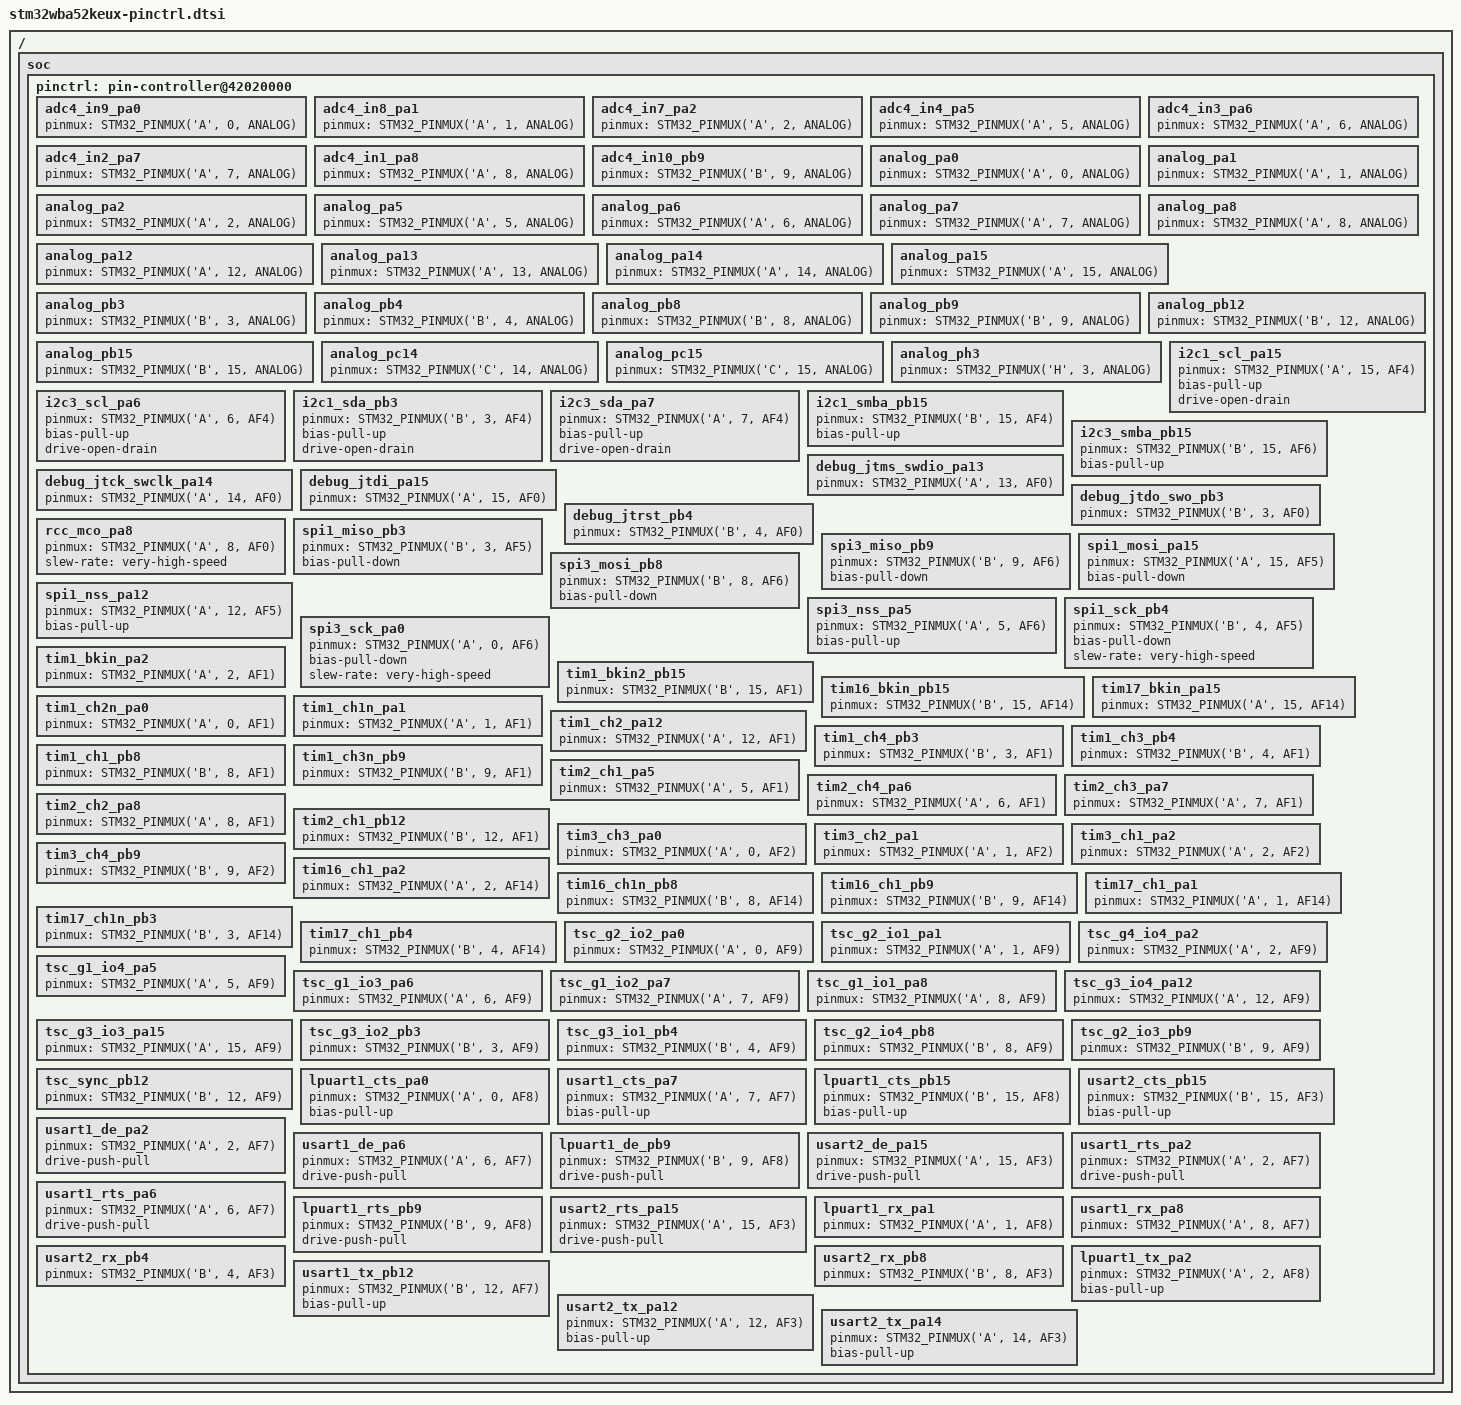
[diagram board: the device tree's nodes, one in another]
/*
 * NOTE: Autogenerated file using genpinctrl.py
 *
 * SPDX-License-Identifier: Apache-2.0
 */

#include <zephyr/dt-bindings/pinctrl/stm32-pinctrl.h>

/ {
	soc {
		pinctrl: pin-controller@42020000 {

			/* ADC_IN / ADC_INN / ADC_INP */

			/omit-if-no-ref/ adc4_in9_pa0: adc4_in9_pa0 {
				pinmux = <STM32_PINMUX('A', 0, ANALOG)>;
			};

			/omit-if-no-ref/ adc4_in8_pa1: adc4_in8_pa1 {
				pinmux = <STM32_PINMUX('A', 1, ANALOG)>;
			};

			/omit-if-no-ref/ adc4_in7_pa2: adc4_in7_pa2 {
				pinmux = <STM32_PINMUX('A', 2, ANALOG)>;
			};

			/omit-if-no-ref/ adc4_in4_pa5: adc4_in4_pa5 {
				pinmux = <STM32_PINMUX('A', 5, ANALOG)>;
			};

			/omit-if-no-ref/ adc4_in3_pa6: adc4_in3_pa6 {
				pinmux = <STM32_PINMUX('A', 6, ANALOG)>;
			};

			/omit-if-no-ref/ adc4_in2_pa7: adc4_in2_pa7 {
				pinmux = <STM32_PINMUX('A', 7, ANALOG)>;
			};

			/omit-if-no-ref/ adc4_in1_pa8: adc4_in1_pa8 {
				pinmux = <STM32_PINMUX('A', 8, ANALOG)>;
			};

			/omit-if-no-ref/ adc4_in10_pb9: adc4_in10_pb9 {
				pinmux = <STM32_PINMUX('B', 9, ANALOG)>;
			};

			/* Analog */

			/omit-if-no-ref/ analog_pa0: analog_pa0 {
				pinmux = <STM32_PINMUX('A', 0, ANALOG)>;
			};

			/omit-if-no-ref/ analog_pa1: analog_pa1 {
				pinmux = <STM32_PINMUX('A', 1, ANALOG)>;
			};

			/omit-if-no-ref/ analog_pa2: analog_pa2 {
				pinmux = <STM32_PINMUX('A', 2, ANALOG)>;
			};

			/omit-if-no-ref/ analog_pa5: analog_pa5 {
				pinmux = <STM32_PINMUX('A', 5, ANALOG)>;
			};

			/omit-if-no-ref/ analog_pa6: analog_pa6 {
				pinmux = <STM32_PINMUX('A', 6, ANALOG)>;
			};

			/omit-if-no-ref/ analog_pa7: analog_pa7 {
				pinmux = <STM32_PINMUX('A', 7, ANALOG)>;
			};

			/omit-if-no-ref/ analog_pa8: analog_pa8 {
				pinmux = <STM32_PINMUX('A', 8, ANALOG)>;
			};

			/omit-if-no-ref/ analog_pa12: analog_pa12 {
				pinmux = <STM32_PINMUX('A', 12, ANALOG)>;
			};

			/omit-if-no-ref/ analog_pa13: analog_pa13 {
				pinmux = <STM32_PINMUX('A', 13, ANALOG)>;
			};

			/omit-if-no-ref/ analog_pa14: analog_pa14 {
				pinmux = <STM32_PINMUX('A', 14, ANALOG)>;
			};

			/omit-if-no-ref/ analog_pa15: analog_pa15 {
				pinmux = <STM32_PINMUX('A', 15, ANALOG)>;
			};

			/omit-if-no-ref/ analog_pb3: analog_pb3 {
				pinmux = <STM32_PINMUX('B', 3, ANALOG)>;
			};

			/omit-if-no-ref/ analog_pb4: analog_pb4 {
				pinmux = <STM32_PINMUX('B', 4, ANALOG)>;
			};

			/omit-if-no-ref/ analog_pb8: analog_pb8 {
				pinmux = <STM32_PINMUX('B', 8, ANALOG)>;
			};

			/omit-if-no-ref/ analog_pb9: analog_pb9 {
				pinmux = <STM32_PINMUX('B', 9, ANALOG)>;
			};

			/omit-if-no-ref/ analog_pb12: analog_pb12 {
				pinmux = <STM32_PINMUX('B', 12, ANALOG)>;
			};

			/omit-if-no-ref/ analog_pb15: analog_pb15 {
				pinmux = <STM32_PINMUX('B', 15, ANALOG)>;
			};

			/omit-if-no-ref/ analog_pc14: analog_pc14 {
				pinmux = <STM32_PINMUX('C', 14, ANALOG)>;
			};

			/omit-if-no-ref/ analog_pc15: analog_pc15 {
				pinmux = <STM32_PINMUX('C', 15, ANALOG)>;
			};

			/omit-if-no-ref/ analog_ph3: analog_ph3 {
				pinmux = <STM32_PINMUX('H', 3, ANALOG)>;
			};

			/* I2C_SCL */

			/omit-if-no-ref/ i2c1_scl_pa15: i2c1_scl_pa15 {
				pinmux = <STM32_PINMUX('A', 15, AF4)>;
				bias-pull-up;
				drive-open-drain;
			};

			/omit-if-no-ref/ i2c3_scl_pa6: i2c3_scl_pa6 {
				pinmux = <STM32_PINMUX('A', 6, AF4)>;
				bias-pull-up;
				drive-open-drain;
			};

			/* I2C_SDA */

			/omit-if-no-ref/ i2c1_sda_pb3: i2c1_sda_pb3 {
				pinmux = <STM32_PINMUX('B', 3, AF4)>;
				bias-pull-up;
				drive-open-drain;
			};

			/omit-if-no-ref/ i2c3_sda_pa7: i2c3_sda_pa7 {
				pinmux = <STM32_PINMUX('A', 7, AF4)>;
				bias-pull-up;
				drive-open-drain;
			};

			/* I2C_SMBA */

			/omit-if-no-ref/ i2c1_smba_pb15: i2c1_smba_pb15 {
				pinmux = <STM32_PINMUX('B', 15, AF4)>;
				bias-pull-up;
			};

			/omit-if-no-ref/ i2c3_smba_pb15: i2c3_smba_pb15 {
				pinmux = <STM32_PINMUX('B', 15, AF6)>;
				bias-pull-up;
			};

			/* JTAG PORT */

			/omit-if-no-ref/ debug_jtms_swdio_pa13: debug_jtms_swdio_pa13 {
				pinmux = <STM32_PINMUX('A', 13, AF0)>;
			};

			/omit-if-no-ref/ debug_jtck_swclk_pa14: debug_jtck_swclk_pa14 {
				pinmux = <STM32_PINMUX('A', 14, AF0)>;
			};

			/omit-if-no-ref/ debug_jtdi_pa15: debug_jtdi_pa15 {
				pinmux = <STM32_PINMUX('A', 15, AF0)>;
			};

			/omit-if-no-ref/ debug_jtdo_swo_pb3: debug_jtdo_swo_pb3 {
				pinmux = <STM32_PINMUX('B', 3, AF0)>;
			};

			/omit-if-no-ref/ debug_jtrst_pb4: debug_jtrst_pb4 {
				pinmux = <STM32_PINMUX('B', 4, AF0)>;
			};

			/* RCC_MCO */

			/omit-if-no-ref/ rcc_mco_pa8: rcc_mco_pa8 {
				pinmux = <STM32_PINMUX('A', 8, AF0)>;
				slew-rate = "very-high-speed";
			};

			/* SPI_MISO */

			/omit-if-no-ref/ spi1_miso_pb3: spi1_miso_pb3 {
				pinmux = <STM32_PINMUX('B', 3, AF5)>;
				bias-pull-down;
			};

			/omit-if-no-ref/ spi3_miso_pb9: spi3_miso_pb9 {
				pinmux = <STM32_PINMUX('B', 9, AF6)>;
				bias-pull-down;
			};

			/* SPI_MOSI */

			/omit-if-no-ref/ spi1_mosi_pa15: spi1_mosi_pa15 {
				pinmux = <STM32_PINMUX('A', 15, AF5)>;
				bias-pull-down;
			};

			/omit-if-no-ref/ spi3_mosi_pb8: spi3_mosi_pb8 {
				pinmux = <STM32_PINMUX('B', 8, AF6)>;
				bias-pull-down;
			};

			/* SPI_NSS */

			/omit-if-no-ref/ spi1_nss_pa12: spi1_nss_pa12 {
				pinmux = <STM32_PINMUX('A', 12, AF5)>;
				bias-pull-up;
			};

			/omit-if-no-ref/ spi3_nss_pa5: spi3_nss_pa5 {
				pinmux = <STM32_PINMUX('A', 5, AF6)>;
				bias-pull-up;
			};

			/* SPI_SCK */

			/omit-if-no-ref/ spi1_sck_pb4: spi1_sck_pb4 {
				pinmux = <STM32_PINMUX('B', 4, AF5)>;
				bias-pull-down;
				slew-rate = "very-high-speed";
			};

			/omit-if-no-ref/ spi3_sck_pa0: spi3_sck_pa0 {
				pinmux = <STM32_PINMUX('A', 0, AF6)>;
				bias-pull-down;
				slew-rate = "very-high-speed";
			};

			/* TIM_BKIN */

			/omit-if-no-ref/ tim1_bkin_pa2: tim1_bkin_pa2 {
				pinmux = <STM32_PINMUX('A', 2, AF1)>;
			};

			/omit-if-no-ref/ tim1_bkin2_pb15: tim1_bkin2_pb15 {
				pinmux = <STM32_PINMUX('B', 15, AF1)>;
			};

			/omit-if-no-ref/ tim16_bkin_pb15: tim16_bkin_pb15 {
				pinmux = <STM32_PINMUX('B', 15, AF14)>;
			};

			/omit-if-no-ref/ tim17_bkin_pa15: tim17_bkin_pa15 {
				pinmux = <STM32_PINMUX('A', 15, AF14)>;
			};

			/* TIM_CH / TIM_CHN */

			/omit-if-no-ref/ tim1_ch2n_pa0: tim1_ch2n_pa0 {
				pinmux = <STM32_PINMUX('A', 0, AF1)>;
			};

			/omit-if-no-ref/ tim1_ch1n_pa1: tim1_ch1n_pa1 {
				pinmux = <STM32_PINMUX('A', 1, AF1)>;
			};

			/omit-if-no-ref/ tim1_ch2_pa12: tim1_ch2_pa12 {
				pinmux = <STM32_PINMUX('A', 12, AF1)>;
			};

			/omit-if-no-ref/ tim1_ch4_pb3: tim1_ch4_pb3 {
				pinmux = <STM32_PINMUX('B', 3, AF1)>;
			};

			/omit-if-no-ref/ tim1_ch3_pb4: tim1_ch3_pb4 {
				pinmux = <STM32_PINMUX('B', 4, AF1)>;
			};

			/omit-if-no-ref/ tim1_ch1_pb8: tim1_ch1_pb8 {
				pinmux = <STM32_PINMUX('B', 8, AF1)>;
			};

			/omit-if-no-ref/ tim1_ch3n_pb9: tim1_ch3n_pb9 {
				pinmux = <STM32_PINMUX('B', 9, AF1)>;
			};

			/omit-if-no-ref/ tim2_ch1_pa5: tim2_ch1_pa5 {
				pinmux = <STM32_PINMUX('A', 5, AF1)>;
			};

			/omit-if-no-ref/ tim2_ch4_pa6: tim2_ch4_pa6 {
				pinmux = <STM32_PINMUX('A', 6, AF1)>;
			};

			/omit-if-no-ref/ tim2_ch3_pa7: tim2_ch3_pa7 {
				pinmux = <STM32_PINMUX('A', 7, AF1)>;
			};

			/omit-if-no-ref/ tim2_ch2_pa8: tim2_ch2_pa8 {
				pinmux = <STM32_PINMUX('A', 8, AF1)>;
			};

			/omit-if-no-ref/ tim2_ch1_pb12: tim2_ch1_pb12 {
				pinmux = <STM32_PINMUX('B', 12, AF1)>;
			};

			/omit-if-no-ref/ tim3_ch3_pa0: tim3_ch3_pa0 {
				pinmux = <STM32_PINMUX('A', 0, AF2)>;
			};

			/omit-if-no-ref/ tim3_ch2_pa1: tim3_ch2_pa1 {
				pinmux = <STM32_PINMUX('A', 1, AF2)>;
			};

			/omit-if-no-ref/ tim3_ch1_pa2: tim3_ch1_pa2 {
				pinmux = <STM32_PINMUX('A', 2, AF2)>;
			};

			/omit-if-no-ref/ tim3_ch4_pb9: tim3_ch4_pb9 {
				pinmux = <STM32_PINMUX('B', 9, AF2)>;
			};

			/omit-if-no-ref/ tim16_ch1_pa2: tim16_ch1_pa2 {
				pinmux = <STM32_PINMUX('A', 2, AF14)>;
			};

			/omit-if-no-ref/ tim16_ch1n_pb8: tim16_ch1n_pb8 {
				pinmux = <STM32_PINMUX('B', 8, AF14)>;
			};

			/omit-if-no-ref/ tim16_ch1_pb9: tim16_ch1_pb9 {
				pinmux = <STM32_PINMUX('B', 9, AF14)>;
			};

			/omit-if-no-ref/ tim17_ch1_pa1: tim17_ch1_pa1 {
				pinmux = <STM32_PINMUX('A', 1, AF14)>;
			};

			/omit-if-no-ref/ tim17_ch1n_pb3: tim17_ch1n_pb3 {
				pinmux = <STM32_PINMUX('B', 3, AF14)>;
			};

			/omit-if-no-ref/ tim17_ch1_pb4: tim17_ch1_pb4 {
				pinmux = <STM32_PINMUX('B', 4, AF14)>;
			};

			/* TSC */

			/omit-if-no-ref/ tsc_g2_io2_pa0: tsc_g2_io2_pa0 {
				pinmux = <STM32_PINMUX('A', 0, AF9)>;
			};

			/omit-if-no-ref/ tsc_g2_io1_pa1: tsc_g2_io1_pa1 {
				pinmux = <STM32_PINMUX('A', 1, AF9)>;
			};

			/omit-if-no-ref/ tsc_g4_io4_pa2: tsc_g4_io4_pa2 {
				pinmux = <STM32_PINMUX('A', 2, AF9)>;
			};

			/omit-if-no-ref/ tsc_g1_io4_pa5: tsc_g1_io4_pa5 {
				pinmux = <STM32_PINMUX('A', 5, AF9)>;
			};

			/omit-if-no-ref/ tsc_g1_io3_pa6: tsc_g1_io3_pa6 {
				pinmux = <STM32_PINMUX('A', 6, AF9)>;
			};

			/omit-if-no-ref/ tsc_g1_io2_pa7: tsc_g1_io2_pa7 {
				pinmux = <STM32_PINMUX('A', 7, AF9)>;
			};

			/omit-if-no-ref/ tsc_g1_io1_pa8: tsc_g1_io1_pa8 {
				pinmux = <STM32_PINMUX('A', 8, AF9)>;
			};

			/omit-if-no-ref/ tsc_g3_io4_pa12: tsc_g3_io4_pa12 {
				pinmux = <STM32_PINMUX('A', 12, AF9)>;
			};

			/omit-if-no-ref/ tsc_g3_io3_pa15: tsc_g3_io3_pa15 {
				pinmux = <STM32_PINMUX('A', 15, AF9)>;
			};

			/omit-if-no-ref/ tsc_g3_io2_pb3: tsc_g3_io2_pb3 {
				pinmux = <STM32_PINMUX('B', 3, AF9)>;
			};

			/omit-if-no-ref/ tsc_g3_io1_pb4: tsc_g3_io1_pb4 {
				pinmux = <STM32_PINMUX('B', 4, AF9)>;
			};

			/omit-if-no-ref/ tsc_g2_io4_pb8: tsc_g2_io4_pb8 {
				pinmux = <STM32_PINMUX('B', 8, AF9)>;
			};

			/omit-if-no-ref/ tsc_g2_io3_pb9: tsc_g2_io3_pb9 {
				pinmux = <STM32_PINMUX('B', 9, AF9)>;
			};

			/omit-if-no-ref/ tsc_sync_pb12: tsc_sync_pb12 {
				pinmux = <STM32_PINMUX('B', 12, AF9)>;
			};

			/* UART_CTS / USART_CTS / LPUART_CTS */

			/omit-if-no-ref/ lpuart1_cts_pa0: lpuart1_cts_pa0 {
				pinmux = <STM32_PINMUX('A', 0, AF8)>;
				bias-pull-up;
			};

			/omit-if-no-ref/ usart1_cts_pa7: usart1_cts_pa7 {
				pinmux = <STM32_PINMUX('A', 7, AF7)>;
				bias-pull-up;
			};

			/omit-if-no-ref/ lpuart1_cts_pb15: lpuart1_cts_pb15 {
				pinmux = <STM32_PINMUX('B', 15, AF8)>;
				bias-pull-up;
			};

			/omit-if-no-ref/ usart2_cts_pb15: usart2_cts_pb15 {
				pinmux = <STM32_PINMUX('B', 15, AF3)>;
				bias-pull-up;
			};

			/* UART_DE / USART_DE / LPUART_DE */

			/omit-if-no-ref/ usart1_de_pa2: usart1_de_pa2 {
				pinmux = <STM32_PINMUX('A', 2, AF7)>;
				drive-push-pull;
			};

			/omit-if-no-ref/ usart1_de_pa6: usart1_de_pa6 {
				pinmux = <STM32_PINMUX('A', 6, AF7)>;
				drive-push-pull;
			};

			/omit-if-no-ref/ lpuart1_de_pb9: lpuart1_de_pb9 {
				pinmux = <STM32_PINMUX('B', 9, AF8)>;
				drive-push-pull;
			};

			/omit-if-no-ref/ usart2_de_pa15: usart2_de_pa15 {
				pinmux = <STM32_PINMUX('A', 15, AF3)>;
				drive-push-pull;
			};

			/* UART_RTS / USART_RTS / LPUART_RTS */

			/omit-if-no-ref/ usart1_rts_pa2: usart1_rts_pa2 {
				pinmux = <STM32_PINMUX('A', 2, AF7)>;
				drive-push-pull;
			};

			/omit-if-no-ref/ usart1_rts_pa6: usart1_rts_pa6 {
				pinmux = <STM32_PINMUX('A', 6, AF7)>;
				drive-push-pull;
			};

			/omit-if-no-ref/ lpuart1_rts_pb9: lpuart1_rts_pb9 {
				pinmux = <STM32_PINMUX('B', 9, AF8)>;
				drive-push-pull;
			};

			/omit-if-no-ref/ usart2_rts_pa15: usart2_rts_pa15 {
				pinmux = <STM32_PINMUX('A', 15, AF3)>;
				drive-push-pull;
			};

			/* UART_RX / USART_RX / LPUART_RX */

			/omit-if-no-ref/ lpuart1_rx_pa1: lpuart1_rx_pa1 {
				pinmux = <STM32_PINMUX('A', 1, AF8)>;
			};

			/omit-if-no-ref/ usart1_rx_pa8: usart1_rx_pa8 {
				pinmux = <STM32_PINMUX('A', 8, AF7)>;
			};

			/omit-if-no-ref/ usart2_rx_pb4: usart2_rx_pb4 {
				pinmux = <STM32_PINMUX('B', 4, AF3)>;
			};

			/omit-if-no-ref/ usart2_rx_pb8: usart2_rx_pb8 {
				pinmux = <STM32_PINMUX('B', 8, AF3)>;
			};

			/* UART_TX / USART_TX / LPUART_TX */

			/omit-if-no-ref/ lpuart1_tx_pa2: lpuart1_tx_pa2 {
				pinmux = <STM32_PINMUX('A', 2, AF8)>;
				bias-pull-up;
			};

			/omit-if-no-ref/ usart1_tx_pb12: usart1_tx_pb12 {
				pinmux = <STM32_PINMUX('B', 12, AF7)>;
				bias-pull-up;
			};

			/omit-if-no-ref/ usart2_tx_pa12: usart2_tx_pa12 {
				pinmux = <STM32_PINMUX('A', 12, AF3)>;
				bias-pull-up;
			};

			/omit-if-no-ref/ usart2_tx_pa14: usart2_tx_pa14 {
				pinmux = <STM32_PINMUX('A', 14, AF3)>;
				bias-pull-up;
			};

		};
	};
};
